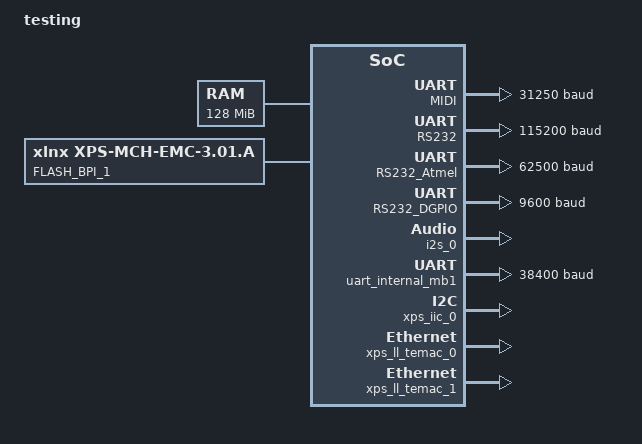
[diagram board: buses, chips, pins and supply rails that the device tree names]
/*
 * Device Tree Generator version: 1.3
 *
 * (C) Copyright 2007-2008 Xilinx, Inc.
 * (C) Copyright 2007-2009 Michal Simek
 *
 * Michal SIMEK <monstr@monstr.eu>
 *
 * This program is free software; you can redistribute it and/or
 * modify it under the terms of the GNU General Public License as
 * published by the Free Software Foundation; either version 2 of
 * the License, or (at your option) any later version.
 *
 * This program is distributed in the hope that it will be useful,
 * but WITHOUT ANY WARRANTY; without even the implied warranty of
 * MERCHANTABILITY or FITNESS FOR A PARTICULAR PURPOSE. See the
 * GNU General Public License for more details.
 *
 * You should have received a copy of the GNU General Public License
 * along with this program; if not, write to the Free Software
 * Foundation, Inc., 59 Temple Place, Suite 330, Boston,
 * MA 02111-1307 USA
 *
 * CAUTION: This file is automatically generated by libgen.
 * Version: Xilinx EDK 11.5 EDK_LS5.70
 *
 * XPS project directory: mblaze
 */

/dts-v1/;
/ {
	#address-cells = <1>;
	#size-cells = <1>;
	compatible = "xlnx,microblaze";
	model = "testing";
	DDR2_1: memory@90000000 {
		device_type = "memory";
		reg = < 0x90000000 0x8000000 >;
	} ;
	aliases {
		ethernet0 = &xps_ll_temac_0;
		ethernet1 = &xps_ll_temac_1;
		serial0 = &RS232;
		serial1 = &RS232_Atmel;
		serial2 = &MIDI;
		serial3 = &uart_internal_mb1;
		serial4 = &RS232_DGPIO;
	} ;
	chosen {
		bootargs = "console=ttyUL0 root=/dev/ram0 load_ramdisk=1 ramdisk_start=4096 prompt_ramdisk=0 BUTTONS=0x00";
		linux,stdout-path = "/plb@0/serial@8c000000";
	} ;
	cpus {
		#address-cells = <1>;
		#cpus = <0x1>;
		#size-cells = <0>;
		microblaze_1: cpu@0 {
			clock-frequency = <125000000>;
			compatible = "xlnx,microblaze-7.20.d";
			d-cache-baseaddr = <0x90000000>;
			d-cache-highaddr = <0x97ffffff>;
			d-cache-line-size = <0x10>;
			d-cache-size = <0x2000>;
			device_type = "cpu";
			i-cache-baseaddr = <0x90000000>;
			i-cache-highaddr = <0x97ffffff>;
			i-cache-line-size = <0x10>;
			i-cache-size = <0x2000>;
			model = "microblaze,7.20.d";
			reg = <0>;
			timebase-frequency = <125000000>;
			xlnx,addr-tag-bits = <0xe>;
			xlnx,allow-dcache-wr = <0x1>;
			xlnx,allow-icache-wr = <0x1>;
			xlnx,area-optimized = <0x0>;
			xlnx,cache-byte-size = <0x2000>;
			xlnx,d-lmb = <0x1>;
			xlnx,d-opb = <0x0>;
			xlnx,d-plb = <0x1>;
			xlnx,data-size = <0x20>;
			xlnx,dcache-addr-tag = <0xe>;
			xlnx,dcache-always-used = <0x1>;
			xlnx,dcache-byte-size = <0x2000>;
			xlnx,dcache-interface = <0x0>;
			xlnx,dcache-line-len = <0x4>;
			xlnx,dcache-use-fsl = <0x1>;
			xlnx,dcache-use-writeback = <0x0>;
			xlnx,debug-enabled = <0x0>;
			xlnx,div-zero-exception = <0x1>;
			xlnx,dopb-bus-exception = <0x0>;
			xlnx,dynamic-bus-sizing = <0x1>;
			xlnx,edge-is-positive = <0x1>;
			xlnx,family = "virtex5";
			xlnx,fpu-exception = <0x0>;
			xlnx,fsl-data-size = <0x20>;
			xlnx,fsl-exception = <0x0>;
			xlnx,fsl-links = <0x0>;
			xlnx,i-lmb = <0x1>;
			xlnx,i-opb = <0x0>;
			xlnx,i-plb = <0x1>;
			xlnx,icache-always-used = <0x1>;
			xlnx,icache-interface = <0x0>;
			xlnx,icache-line-len = <0x4>;
			xlnx,icache-use-fsl = <0x1>;
			xlnx,ill-opcode-exception = <0x1>;
			xlnx,instance = "microblaze_1";
			xlnx,interconnect = <0x1>;
			xlnx,interrupt-is-edge = <0x0>;
			xlnx,iopb-bus-exception = <0x0>;
			xlnx,mmu-dtlb-size = <0x4>;
			xlnx,mmu-itlb-size = <0x2>;
			xlnx,mmu-tlb-access = <0x3>;
			xlnx,mmu-zones = <0x10>;
			xlnx,number-of-pc-brk = <0x1>;
			xlnx,number-of-rd-addr-brk = <0x0>;
			xlnx,number-of-wr-addr-brk = <0x0>;
			xlnx,opcode-0x0-illegal = <0x1>;
			xlnx,pvr = <0x2>;
			xlnx,pvr-user1 = <0x0>;
			xlnx,pvr-user2 = <0x0>;
			xlnx,reset-msr = <0x0>;
			xlnx,sco = <0x0>;
			xlnx,unaligned-exceptions = <0x1>;
			xlnx,use-barrel = <0x1>;
			xlnx,use-dcache = <0x1>;
			xlnx,use-div = <0x1>;
			xlnx,use-ext-brk = <0x0>;
			xlnx,use-ext-nm-brk = <0x0>;
			xlnx,use-extended-fsl-instr = <0x0>;
			xlnx,use-fpu = <0x0>;
			xlnx,use-hw-mul = <0x2>;
			xlnx,use-icache = <0x1>;
			xlnx,use-interrupt = <0x1>;
			xlnx,use-mmu = <0x0>;
			xlnx,use-msr-instr = <0x1>;
			xlnx,use-pcmp-instr = <0x1>;
		} ;
	} ;
	plb_1_0: plb@0 {
		#address-cells = <1>;
		#size-cells = <1>;
		compatible = "xlnx,plb-v46-1.04.a", "xlnx,plb-v46-1.00.a", "simple-bus";
		ranges ;
		FLASH_BPI_1: flash@8a000000 {
			bank-width = <2>;
			compatible = "xlnx,xps-mch-emc-3.01.a", "cfi-flash";
			reg = < 0x8a000000 0x1000000 >;
			xlnx,family = "virtex5";
			xlnx,include-datawidth-matching-0 = <0x1>;
			xlnx,include-datawidth-matching-1 = <0x0>;
			xlnx,include-datawidth-matching-2 = <0x0>;
			xlnx,include-datawidth-matching-3 = <0x0>;
			xlnx,include-negedge-ioregs = <0x0>;
			xlnx,include-plb-ipif = <0x1>;
			xlnx,include-wrbuf = <0x1>;
			xlnx,max-mem-width = <0x10>;
			xlnx,mch-native-dwidth = <0x20>;
			xlnx,mch-splb-awidth = <0x20>;
			xlnx,mch-splb-clk-period-ps = <0x1f40>;
			xlnx,mch0-accessbuf-depth = <0x10>;
			xlnx,mch0-protocol = <0x0>;
			xlnx,mch0-rddatabuf-depth = <0x10>;
			xlnx,mch1-accessbuf-depth = <0x10>;
			xlnx,mch1-protocol = <0x0>;
			xlnx,mch1-rddatabuf-depth = <0x10>;
			xlnx,mch2-accessbuf-depth = <0x10>;
			xlnx,mch2-protocol = <0x0>;
			xlnx,mch2-rddatabuf-depth = <0x10>;
			xlnx,mch3-accessbuf-depth = <0x10>;
			xlnx,mch3-protocol = <0x0>;
			xlnx,mch3-rddatabuf-depth = <0x10>;
			xlnx,mem0-width = <0x10>;
			xlnx,mem1-width = <0x20>;
			xlnx,mem2-width = <0x20>;
			xlnx,mem3-width = <0x20>;
			xlnx,num-banks-mem = <0x1>;
			xlnx,num-channels = <0x0>;
			xlnx,pagemode-flash-0 = <0x0>;
			xlnx,pagemode-flash-1 = <0x0>;
			xlnx,pagemode-flash-2 = <0x0>;
			xlnx,pagemode-flash-3 = <0x0>;
			xlnx,priority-mode = <0x0>;
			xlnx,synch-mem-0 = <0x0>;
			xlnx,synch-mem-1 = <0x0>;
			xlnx,synch-mem-2 = <0x0>;
			xlnx,synch-mem-3 = <0x0>;
			xlnx,synch-pipedelay-0 = <0x2>;
			xlnx,synch-pipedelay-1 = <0x2>;
			xlnx,synch-pipedelay-2 = <0x2>;
			xlnx,synch-pipedelay-3 = <0x2>;
			xlnx,tavdv-ps-mem-0 = <0x14c08>;
			xlnx,tavdv-ps-mem-1 = <0x3a98>;
			xlnx,tavdv-ps-mem-2 = <0x3a98>;
			xlnx,tavdv-ps-mem-3 = <0x3a98>;
			xlnx,tcedv-ps-mem-0 = <0x14c08>;
			xlnx,tcedv-ps-mem-1 = <0x3a98>;
			xlnx,tcedv-ps-mem-2 = <0x3a98>;
			xlnx,tcedv-ps-mem-3 = <0x3a98>;
			xlnx,thzce-ps-mem-0 = <0x5dc0>;
			xlnx,thzce-ps-mem-1 = <0x1b58>;
			xlnx,thzce-ps-mem-2 = <0x1b58>;
			xlnx,thzce-ps-mem-3 = <0x1b58>;
			xlnx,thzoe-ps-mem-0 = <0x5dc0>;
			xlnx,thzoe-ps-mem-1 = <0x1b58>;
			xlnx,thzoe-ps-mem-2 = <0x1b58>;
			xlnx,thzoe-ps-mem-3 = <0x1b58>;
			xlnx,tlzwe-ps-mem-0 = <0x0>;
			xlnx,tlzwe-ps-mem-1 = <0x0>;
			xlnx,tlzwe-ps-mem-2 = <0x0>;
			xlnx,tlzwe-ps-mem-3 = <0x0>;
			xlnx,tpacc-ps-flash-0 = <0x61a8>;
			xlnx,tpacc-ps-flash-1 = <0x61a8>;
			xlnx,tpacc-ps-flash-2 = <0x61a8>;
			xlnx,tpacc-ps-flash-3 = <0x61a8>;
			xlnx,twc-ps-mem-0 = <0x11170>;
			xlnx,twc-ps-mem-1 = <0x3a98>;
			xlnx,twc-ps-mem-2 = <0x3a98>;
			xlnx,twc-ps-mem-3 = <0x3a98>;
			xlnx,twp-ps-mem-0 = <0xc350>;
			xlnx,twp-ps-mem-1 = <0x2ee0>;
			xlnx,twp-ps-mem-2 = <0x2ee0>;
			xlnx,twp-ps-mem-3 = <0x2ee0>;
			xlnx,xcl0-linesize = <0x4>;
			xlnx,xcl0-writexfer = <0x1>;
			xlnx,xcl1-linesize = <0x4>;
			xlnx,xcl1-writexfer = <0x1>;
			xlnx,xcl2-linesize = <0x4>;
			xlnx,xcl2-writexfer = <0x1>;
			xlnx,xcl3-linesize = <0x4>;
			xlnx,xcl3-writexfer = <0x1>;
		} ;
		MIDI: serial@85000000 {
			clock-frequency = <125000000>;
			compatible = "xlnx,xps-uartlite-1.01.a", "xlnx,xps-uartlite-1.00.a";
			current-speed = <31250>;
			device_type = "serial";
			interrupt-parent = <&xps_intc_1>;
			interrupts = < 8 0 >;
			port-number = <2>;
			reg = < 0x85000000 0x10000 >;
			xlnx,baudrate = <0x7a12>;
			xlnx,data-bits = <0x8>;
			xlnx,family = "virtex5";
			xlnx,odd-parity = <0x1>;
			xlnx,use-parity = <0x0>;
		} ;
		RS232: serial@8c000000 {
			clock-frequency = <125000000>;
			compatible = "xlnx,xps-uartlite-1.01.a", "xlnx,xps-uartlite-1.00.a";
			current-speed = <115200>;
			device_type = "serial";
			interrupt-parent = <&xps_intc_1>;
			interrupts = < 5 0 >;
			port-number = <0>;
			reg = < 0x8c000000 0x10000 >;
			xlnx,baudrate = <0x1c200>;
			xlnx,data-bits = <0x8>;
			xlnx,family = "virtex5";
			xlnx,odd-parity = <0x1>;
			xlnx,use-parity = <0x0>;
		} ;
		RS232_Atmel: serial@8b000000 {
			clock-frequency = <125000000>;
			compatible = "xlnx,xps-uartlite-1.01.a", "xlnx,xps-uartlite-1.00.a";
			current-speed = <62500>;
			device_type = "serial";
			interrupt-parent = <&xps_intc_1>;
			interrupts = < 6 0 >;
			port-number = <1>;
			reg = < 0x8b000000 0x10000 >;
			xlnx,baudrate = <0xf424>;
			xlnx,data-bits = <0x8>;
			xlnx,family = "virtex5";
			xlnx,odd-parity = <0x1>;
			xlnx,use-parity = <0x0>;
		} ;
		RS232_DGPIO: serial@86000000 {
			clock-frequency = <125000000>;
			compatible = "xlnx,xps-uart16550-3.00.a", "ns16550";
			current-speed = <9600>;
			device_type = "serial";
			interrupt-parent = <&xps_intc_1>;
			interrupts = < 9 2 >;
			reg = < 0x86000000 0x10000 >;
			reg-offset = <0x1003>;
			reg-shift = <2>;
			xlnx,external-xin-clk-hz = <0x17d7840>;
			xlnx,family = "virtex5";
			xlnx,has-external-rclk = <0x0>;
			xlnx,has-external-xin = <0x0>;
			xlnx,is-a-16550 = <0x1>;
		} ;
		i2s_0: iis2424-g@8e000000 {
			compatible = "xlnx,iis2424-g-1.00.c";
			reg = < 0x8e000000 0x10000 >;
			xlnx,family = "virtex5";
			xlnx,include-dphase-timer = <0x1>;
		} ;
		mpmc@90000000 {
			#address-cells = <1>;
			#size-cells = <1>;
			compatible = "xlnx,mpmc-5.04.a";
		} ;
		oled_spi_0: xps-spi@89000000 {
			compatible = "xlnx,xps-spi-2.01.b", "xlnx,xps-spi-2.00.a";
			interrupt-parent = <&xps_intc_1>;
			interrupts = < 4 2 >;
			reg = < 0x89000000 0x10000 >;
			xlnx,family = "virtex5";
			xlnx,fifo-exist = <0x1>;
			xlnx,num-ss-bits = <0x1>;
			xlnx,num-transfer-bits = <0x8>;
			xlnx,sck-ratio = <0x20>;
			generic@0 {
				compatible = "generic,spidev";
				linux,modalias = "spidev";
				spi-max-frequency = <3906250>;
				reg = <0x0>;
			} ;
		} ;
		uart_internal_mb1: serial@8d000000 {
			clock-frequency = <125000000>;
			compatible = "xlnx,xps-uartlite-1.01.a", "xlnx,xps-uartlite-1.00.a";
			current-speed = <38400>;
			device_type = "serial";
			interrupt-parent = <&xps_intc_1>;
			interrupts = < 7 0 >;
			port-number = <3>;
			reg = < 0x8d000000 0x10 >;
			xlnx,baudrate = <0x9600>;
			xlnx,data-bits = <0x8>;
			xlnx,family = "virtex5";
			xlnx,odd-parity = <0x1>;
			xlnx,use-parity = <0x0>;
		} ;
		xps_gpio_0: gpio@81000000 {
			compatible = "xlnx,xps-gpio-2.00.a", "xlnx,xps-gpio-1.00.a";
			reg = < 0x81000000 0x10000 >;
			xlnx,all-inputs = <0x0>;
			xlnx,all-inputs-2 = <0x0>;
			xlnx,dout-default = <0x80>;
			xlnx,dout-default-2 = <0x0>;
			xlnx,family = "virtex5";
			xlnx,gpio-width = <0x8>;
			xlnx,gpio2-width = <0x20>;
			xlnx,interrupt-present = <0x0>;
			xlnx,is-dual = <0x0>;
			xlnx,tri-default = <0xffffffff>;
			xlnx,tri-default-2 = <0xffffffff>;
		} ;
		xps_iic_0: i2c@8f000000 {
			compatible = "xlnx,xps-iic-2.02.a", "xlnx,xps-iic-2.00.a";
			reg = < 0x8f000000 0x10000 >;
			xlnx,clk-freq = <0x7735940>;
			xlnx,family = "virtex5";
			xlnx,gpo-width = <0x1>;
			xlnx,iic-freq = <0x9c40>;
			xlnx,scl-inertial-delay = <0x1>;
			xlnx,sda-inertial-delay = <0x1>;
			xlnx,ten-bit-adr = <0x0>;
		} ;
		xps_intc_1: interrupt-controller@82000000 {
			#interrupt-cells = <0x2>;
			compatible = "xlnx,xps-intc-2.00.a", "xlnx,xps-intc-1.00.a";
			interrupt-controller ;
			reg = < 0x82000000 0x10000 >;
			xlnx,kind-of-intr = <0x1e1>;
			xlnx,num-intr-inputs = <0xa>;
		} ;
		xps_ll_fifo_1: xps-ll-fifo@84000000 {
			compatible = "xlnx,xps-ll-fifo-1.02.a";
			interrupt-parent = <&xps_intc_1>;
			interrupts = < 2 2 >;
			reg = < 0x84000000 0x10000 >;
			xlnx,family = "virtex5";
		} ;
		xps_ll_temac_0: xps-ll-temac@83000000 {
			#address-cells = <1>;
			#size-cells = <1>;
			compatible = "xlnx,compound";
			ethernet@83000000 {
				compatible = "xlnx,xps-ll-temac-2.03.z", "xlnx,xps-ll-temac-1.00.a";
				device_type = "network";
				interrupt-parent = <&xps_intc_1>;
				interrupts = < 3 2 >;
				llink-connected = <&xps_ll_fifo_1>;
				local-mac-address = [ 00 0a 35 eb 82 00 ];
				reg = < 0x83000000 0x40 >;
				xlnx,avb = <0x0>;
				xlnx,bus2core-clk-ratio = <0x1>;
				xlnx,mcast-extend = <0x1>;
				xlnx,phy-type = <0x4>;
				xlnx,phyaddr = <0x5>;
				xlnx,rxcsum = <0x0>;
				xlnx,rxfifo = <0x1000>;
				xlnx,rxvlan-strp = <0x0>;
				xlnx,rxvlan-tag = <0x0>;
				xlnx,rxvlan-tran = <0x0>;
				xlnx,stats = <0x0>;
				xlnx,temac-type = <0x0>;
				xlnx,txcsum = <0x0>;
				xlnx,txfifo = <0x1000>;
				xlnx,txvlan-strp = <0x0>;
				xlnx,txvlan-tag = <0x0>;
				xlnx,txvlan-tran = <0x0>;
			} ;
		} ;
		xps_ll_temac_1: xps-ll-temac@00000000 {
			#address-cells = <1>;
			#size-cells = <1>;
			compatible = "xlnx,compound";
			ethernet@00000000 {
				compatible = "xlnx,xps-ll-temac-2.03.z", "xlnx,xps-ll-temac-1.00.a";
				device_type = "network";
				reg = < 0x00000000 0x40 >;
				xlnx,phy-type = <0x4>;
				xlnx,temac-type = <0x0>;
			} ;
		} ;
		xps_timer_0: timer@88000000 {
			compatible = "xlnx,xps-timer-1.01.b", "xlnx,xps-timer-1.00.a";
			interrupt-parent = <&xps_intc_1>;
			interrupts = < 1 2 >;
			reg = < 0x88000000 0x10000 >;
			xlnx,count-width = <0x20>;
			xlnx,family = "virtex5";
			xlnx,gen0-assert = <0x1>;
			xlnx,gen1-assert = <0x1>;
			xlnx,one-timer-only = <0x0>;
			xlnx,trig0-assert = <0x1>;
			xlnx,trig1-assert = <0x1>;
		} ;
	} ;
}  ;
